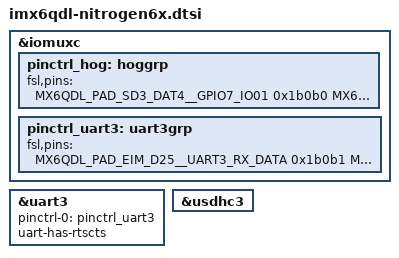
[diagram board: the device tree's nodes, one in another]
// SPDX-License-Identifier: GPL-2.0+
//
// Copyright 2013-2019 Boundary Devices, Inc.
// Copyright 2012 Freescale Semiconductor, Inc.
// Copyright 2011 Linaro Ltd.

#include "imx6qdl-sabrelite.dtsi"

&iomuxc {
	pinctrl_hog: hoggrp {
		fsl,pins = <
			/* Spare */
			MX6QDL_PAD_SD3_DAT4__GPIO7_IO01		0x1b0b0
			MX6QDL_PAD_NANDF_D7__GPIO2_IO07		0x1b0b0
			MX6QDL_PAD_GPIO_4__GPIO1_IO04		0x1b0b0
		>;
	};

	pinctrl_uart3: uart3grp {
		fsl,pins = <
			MX6QDL_PAD_EIM_D25__UART3_RX_DATA	0x1b0b1
			MX6QDL_PAD_EIM_D24__UART3_TX_DATA	0x1b0b1
			MX6QDL_PAD_EIM_D23__UART3_CTS_B		0x1b0b1
			MX6QDL_PAD_EIM_D31__UART3_RTS_B		0x1b0b1
		>;
	};
};

&uart3 {
	pinctrl-names = "default";
	pinctrl-0 = <&pinctrl_uart3>;
	uart-has-rtscts;
	status = "okay";
};

&usdhc3 {
	/delete-property/ wp-gpios;
};
